# psc3_p8_ppca register map
Vendor: Infineon Technologies; Series: PSC3_P8; File version: 1.0
CPU: CM33 r0p1, little endian, MPU, FPU, DSP, VTOR, 3 interrupt priority bits, 143 interrupts
Registers are 32-bit, read-write, reset 0x0 unless marked. A register's access mark holds for its fields unless they carry their own. Offsets are from the block's base; [hi:lo] are bit positions; lines under a group give offsets from that group; {n}, {i} and the like mark numbered series; 'fields as' and 'values as' point back to an identical list.

## IPC
Base 0x681D0000
{0x0+0x20*i} STRUCT[{i}] (i=0..7) group — IPC structure
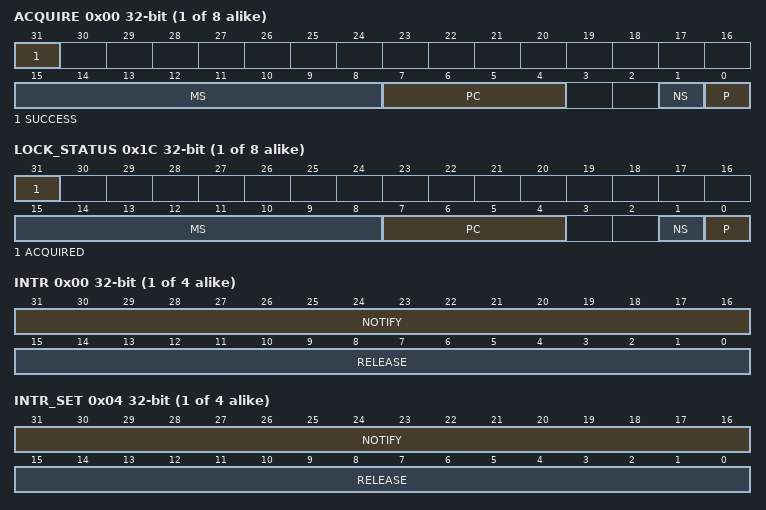
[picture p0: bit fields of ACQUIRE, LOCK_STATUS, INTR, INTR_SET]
  0x00 ACQUIRE ro (reset mask 0x80000000) — IPC acquire
    [31] SUCCESS
    [15:8] MS — This field specifies the bus master identifier that successfully acquired the lock.
    [7:4] PC
    [1] NS
    [0] P
  0x04 RELEASE wo — IPC release
    [15:0] INTR_RELEASE — Writing this field releases a lock and allows for the generation of release events to the IPC interrupt structures, but only when the lock is acquired (LOCK_STATUS.ACQUIRED is '1'). The IPC release cause fields associated with this IPC structure are set to '1', but only for those IPC interrupt structures for which the corresponding bit field in INTR_RELEASE[] is set to '1'. SW writes a '1' to the bit fields to generate a release event. Due to the transient nature of this event, SW always reads a '0' from this field.
  0x08 NOTIFY wo — IPC notification
    [15:0] INTR_NOTIFY — This field allows for the generation of notification events to the IPC interrupt structures. The IPC notification cause fields associated with this IPC structure are set to '1', but only for those IPC interrupt structures for which the corresponding bit field in INTR_NOTIFY[] is set to '1'. SW writes a '1' to the bit fields to generate a notify event. Due to the transient nature of this event, SW always reads a '0' from this field.
  0x0C DATA0 reset not defined — IPC data 0
    [31:0] DATA — This field holds a 32-bit data element that is associated with the IPC structure.
  0x10 DATA1 reset not defined — IPC data 1
    fields as STRUCT[0].DATA0
  0x1C LOCK_STATUS ro (reset mask 0x80000000) — IPC lock status
    [31] ACQUIRED
    [15:8] MS — This field specifies the bus master identifier that successfully acquired the lock.
    [7:4] PC
    [1] NS
    [0] P
{0x1000+0x20*i} INTR_STRUCT[{i}] (i=0..3) group — IPC interrupt structure
  0x00 INTR — Interrupt
    [31:16] NOTIFY write-1-clears — These interrupt cause fields are activated (HW sets the field to '1') when a IPC notification event is detected. One bit field for each master. SW writes a '1' to these field to clear the interrupt cause.
    [15:0] RELEASE write-1-clears — These interrupt cause fields are activated (HW sets the field to '1') when a IPC release event is detected. One bit field for each master. SW writes a '1' to these field to clear the interrupt cause.
  0x04 INTR_SET — Interrupt set
    [31:16] NOTIFY write-1-sets — SW writes a '1' to this field to set the corresponding field in the INTR register.
    [15:0] RELEASE write-1-sets — SW writes a '1' to this field to set the corresponding field in the INTR register.
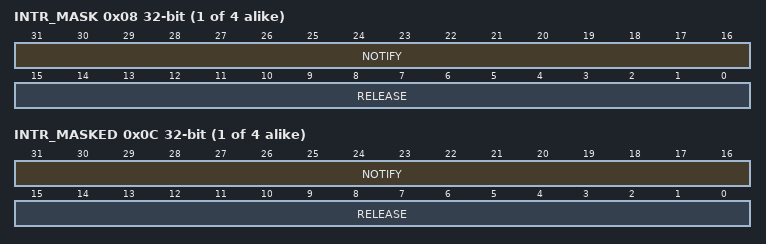
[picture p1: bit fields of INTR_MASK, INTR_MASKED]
  0x08 INTR_MASK — Interrupt mask
    [31:16] NOTIFY — Mask bit for corresponding field in the INTR register.
    [15:0] RELEASE — Mask bit for corresponding field in the INTR register.
  0x0C INTR_MASKED ro — Interrupt masked
    [31:16] NOTIFY — Logical and of corresponding INTR and INTR_MASK fields.
    [15:0] RELEASE — Logical and of corresponding request and mask bits.

## MXWOUND — 0
Base 0x68240000
0x00 CTL — MXWOUND Control Reg
  [31] ENABLED — IP enable: '0': Disabled. IP SC logic is not clocked (but does not change the state). '1': Enabled. IP SC logic is clocked.
0x100 MXWOUND_PROP group — 0
  0x00 PROP — Property value register
    [31:0] PROP — Property bit value

## DEBUG600
Base 0x68250000
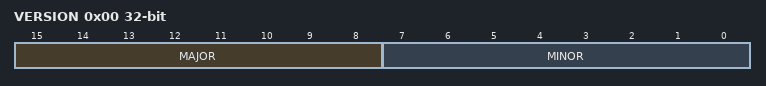
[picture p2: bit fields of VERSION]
0x00 VERSION ro reset not defined — IP Version Information
  [15:8] MAJOR — IP Major Revision Number
  [7:0] MINOR — IP Minor Revision Number

## HSIOM — IO Matrix (IOM)
Base 0x68400000
{0x0+0x10*i} PRT[{i}] (i=0..9) group — HSIOM port registers
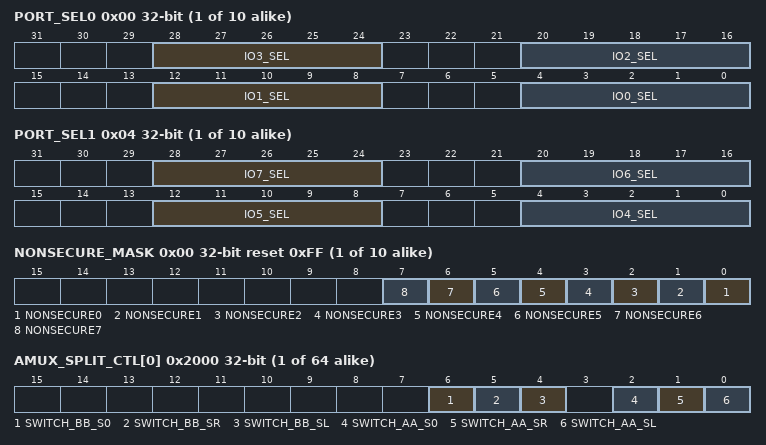
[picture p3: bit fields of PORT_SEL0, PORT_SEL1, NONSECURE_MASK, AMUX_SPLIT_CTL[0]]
  0x00 PORT_SEL0 — Port selection 0
    [28:24] IO3_SEL — Selects connection for IO pin 3 route.
    [20:16] IO2_SEL — Selects connection for IO pin 2 route.
    [12:8] IO1_SEL — Selects connection for IO pin 1 route.
    [4:0] IO0_SEL — Selects connection for IO pin 0 route.
      0=GPIO (GPIO controls 'out'); 1=GPIO_DSI (GPIO controls 'out', DSI controls 'output enable'); 2=DSI_DSI (DSI controls 'out' and 'output enable'); 3=DSI_GPIO (DSI controls 'out', GPIO controls 'output enable'); 4=AMUXA (Analog mux bus A); 5=AMUXB (Analog mux bus B); 6=AMUXA_DSI (Analog mux bus A, DSI control); 7=AMUXB_DSI (Analog mux bus B, DSI control); {v}=ACT_{v-8} (Active functionality {v-8}) (v=8..11); {v}=DS_{v-12} (DeepSleep functionality {v-12}) (v=12..15); {v}=ACT_{v-12} (Active functionality {v-12}) (v=16..27); {v}=DS_{v-24} (DeepSleep functionality {v-24}) (v=28..31)
  0x04 PORT_SEL1 — Port selection 1
    [28:24] IO7_SEL — Selects connection for IO pin 7 route.
    [20:16] IO6_SEL — Selects connection for IO pin 6 route.
    [12:8] IO5_SEL — Selects connection for IO pin 5 route.
    [4:0] IO4_SEL — Selects connection for IO pin 4 route. See PORT_SEL0 for connection details.
{0x1000+0x10*i} SECURE_PRT[{i}] (i=0..9) group — HSIOM secure attribute port registers
  0x00 NONSECURE_MASK reset 0xFF
    [n] NONSECURE{n} (n=0..7) — Non-secure attribute for IO{n}. 0 - Allows Secure access only. 1 - Allows Non-secure access only.
{0x2000+4i} AMUX_SPLIT_CTL[{i}] (i=0..63) — AMUX splitter cell control
  [6] SWITCH_BB_S0 — T-switch control for AMUXBUSB vssa/ground switch.
  [5] SWITCH_BB_SR — T-switch control for Right AMUXBUSB switch.
  [4] SWITCH_BB_SL — T-switch control for Left AMUXBUSB switch.
  [2] SWITCH_AA_S0 — T-switch control for AMUXBUSA vssa/ground switch: '0': switch open. '1': switch closed.
  [1] SWITCH_AA_SR — T-switch control for Right AMUXBUSA switch: '0': switch open. '1': switch closed.
  [0] SWITCH_AA_SL — T-switch control for Left AMUXBUSA switch: '0': switch open. '1': switch closed.
{0x2200+4i} MONITOR_CTL_{i} (i=0..3) — Power/Ground Monitor cell control {i}
  [31:0] MONITOR_EN — control for switch, which connects the power/ground supply to AMUXBUS_A/B respectively when switch is closed: '0': switch open. '1': switch closed.
